# S32K324_M7 register map
Vendor: NXP Semiconductors; File version: 1.1
CPU: CM7 r0p1, little endian, MPU, FPU, VTOR, 4 interrupt priority bits
Registers are 32-bit, read-write, reset 0x0 unless marked. A register's access mark holds for its fields unless they carry their own. Offsets are from the block's base; [hi:lo] are bit positions; {n}, {i} and the like mark numbered series; 'fields as' and 'values as' point back to an identical list.

## EMAC (part 2 of 3)
Base 0x40480000
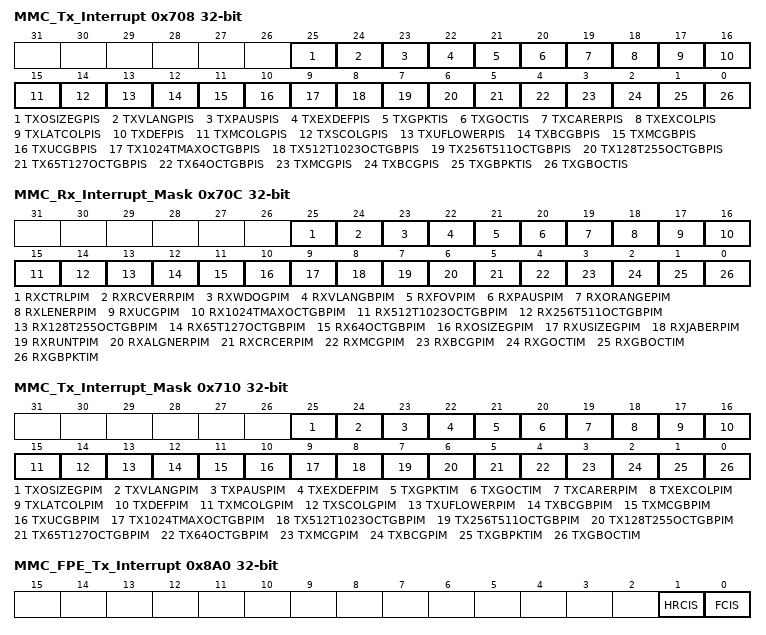
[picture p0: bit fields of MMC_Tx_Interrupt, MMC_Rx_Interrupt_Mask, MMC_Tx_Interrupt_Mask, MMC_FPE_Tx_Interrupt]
0x708 MMC_Tx_Interrupt ro — MMC Transmit Interrupt
  [all] fields
    0=INACTIVE (Not detected); 1=ACTIVE (Detected)
  [25] TXOSIZEGPIS — MMC Transmit Oversize Good Packet Counter Interrupt Status
  [24] TXVLANGPIS — MMC Transmit VLAN Good Packet Counter Interrupt Status
  [23] TXPAUSPIS — MMC Transmit Pause Packet Counter Interrupt Status
  [22] TXEXDEFPIS — MMC Transmit Excessive Deferral Packet Counter Interrupt Status
  [21] TXGPKTIS — MMC Transmit Good Packet Counter Interrupt Status
  [20] TXGOCTIS — MMC Transmit Good Octet Counter Interrupt Status
  [19] TXCARERPIS — MMC Transmit Carrier Error Packet Counter Interrupt Status
  [18] TXEXCOLPIS — MMC Transmit Excessive Collision Packet Counter Interrupt Status
  [17] TXLATCOLPIS — MMC Transmit Late Collision Packet Counter Interrupt Status
  [16] TXDEFPIS — MMC Transmit Deferred Packet Counter Interrupt Status
  [15] TXMCOLGPIS — MMC Transmit Multiple Collision Good Packet Counter Interrupt Status
  [14] TXSCOLGPIS — MMC Transmit Single Collision Good Packet Counter Interrupt Status
  [13] TXUFLOWERPIS — MMC Transmit Underflow Error Packet Counter Interrupt Status
  [12] TXBCGBPIS — MMC Transmit Broadcast Good Bad Packet Counter Interrupt Status
  [11] TXMCGBPIS — MMC Transmit Multicast Good Bad Packet Counter Interrupt Status
  [10] TXUCGBPIS — MMC Transmit Unicast Good Bad Packet Counter Interrupt Status
  [9] TX1024TMAXOCTGBPIS — MMC Transmit 1024 To Maximum Octet Good Bad Packet Counter Interrupt Status
  [8] TX512T1023OCTGBPIS — MMC Transmit 512 To 1023 Octet Good Bad Packet Counter Interrupt Status
  [7] TX256T511OCTGBPIS — MMC Transmit 256 To 511 Octet Good Bad Packet Counter Interrupt Status
  [6] TX128T255OCTGBPIS — MMC Transmit 128 To 255 Octet Good Bad Packet Counter Interrupt Status
  [5] TX65T127OCTGBPIS — MMC Transmit 65 To 127 Octet Good Bad Packet Counter Interrupt Status
  [4] TX64OCTGBPIS — MMC Transmit 64-Octet Good Bad Packet Counter Interrupt Status
  [3] TXMCGPIS — MMC Transmit Multicast Good Packet Counter Interrupt Status
  [2] TXBCGPIS — MMC Transmit Broadcast Good Packet Counter Interrupt Status
  [1] TXGBPKTIS — MMC Transmit Good Bad Packet Counter Interrupt Status
  [0] TXGBOCTIS — MMC Transmit Good Bad Octet Counter Interrupt Status
0x70C MMC_Rx_Interrupt_Mask — MMC Receive Interrupt Mask
  [all] fields
    0=DISABLE (Disabled); 1=ENABLE (Enabled)
  [25] RXCTRLPIM — MMC Receive Control Packet Counter Interrupt Mask
  [24] RXRCVERRPIM — MMC Receive Error Packet Counter Interrupt Mask
  [23] RXWDOGPIM — MMC Receive Watchdog Error Packet Counter Interrupt Mask
  [22] RXVLANGBPIM — MMC Receive VLAN Good Bad Packet Counter Interrupt Mask
  [21] RXFOVPIM — MMC Receive FIFO Overflow Packet Counter Interrupt Mask
  [20] RXPAUSPIM — MMC Receive Pause Packet Counter Interrupt Mask
  [19] RXORANGEPIM — MMC Receive Out-Of-Range Error Packet Counter Interrupt Mask
  [18] RXLENERPIM — MMC Receive Length Error Packet Counter Interrupt Mask
  [17] RXUCGPIM — MMC Receive Unicast Good Packet Counter Interrupt Mask
  [16] RX1024TMAXOCTGBPIM — MMC Receive 1024 To Maximum Octet Good Bad Packet Counter Interrupt Mask
  [15] RX512T1023OCTGBPIM — MMC Receive 512 To 1023 Octet Good Bad Packet Counter Interrupt Mask
  [14] RX256T511OCTGBPIM — MMC Receive 256 To 511 Octet Good Bad Packet Counter Interrupt Mask
  [13] RX128T255OCTGBPIM — MMC Receive 128 To 255 Octet Good Bad Packet Counter Interrupt Mask
  [12] RX65T127OCTGBPIM — MMC Receive 65 To 127 Octet Good Bad Packet Counter Interrupt Mask
  [11] RX64OCTGBPIM — MMC Receive 64-Octet Good Bad Packet Counter Interrupt Mask
  [10] RXOSIZEGPIM — MMC Receive Oversize Good Packet Counter Interrupt Mask
  [9] RXUSIZEGPIM — MMC Receive Undersize Good Packet Counter Interrupt Mask
  [8] RXJABERPIM — MMC Receive Jabber Error Packet Counter Interrupt Mask
  [7] RXRUNTPIM — MMC Receive Runt Packet Counter Interrupt Mask
  [6] RXALGNERPIM — MMC Receive Alignment Error Packet Counter Interrupt Mask
  [5] RXCRCERPIM — MMC Receive CRC Error Packet Counter Interrupt Mask
  [4] RXMCGPIM — MMC Receive Multicast Good Packet Counter Interrupt Mask
  [3] RXBCGPIM — MMC Receive Broadcast Good Packet Counter Interrupt Mask
  [2] RXGOCTIM — MMC Receive Good Octet Counter Interrupt Mask
  [1] RXGBOCTIM — MMC Receive Good Bad Octet Counter Interrupt Mask
  [0] RXGBPKTIM — MMC Receive Good Bad Packet Counter Interrupt Mask
0x710 MMC_Tx_Interrupt_Mask — MMC Transmit Interrupt Mask
  [all] fields
    0=DISABLE (Disabled); 1=ENABLE (Enabled)
  [25] TXOSIZEGPIM — MMC Transmit Oversize Good Packet Counter Interrupt Mask
  [24] TXVLANGPIM — MMC Transmit VLAN Good Packet Counter Interrupt Mask
  [23] TXPAUSPIM — MMC Transmit Pause Packet Counter Interrupt Mask
  [22] TXEXDEFPIM — MMC Transmit Excessive Deferral Packet Counter Interrupt Mask
  [21] TXGPKTIM — MMC Transmit Good Packet Counter Interrupt Mask
  [20] TXGOCTIM — MMC Transmit Good Octet Counter Interrupt Mask
  [19] TXCARERPIM — MMC Transmit Carrier Error Packet Counter Interrupt Mask
  [18] TXEXCOLPIM — MMC Transmit Excessive Collision Packet Counter Interrupt Mask
  [17] TXLATCOLPIM — MMC Transmit Late Collision Packet Counter Interrupt Mask
  [16] TXDEFPIM — MMC Transmit Deferred Packet Counter Interrupt Mask
  [15] TXMCOLGPIM — MMC Transmit Multiple Collision Good Packet Counter Interrupt Mask
  [14] TXSCOLGPIM — MMC Transmit Single Collision Good Packet Counter Interrupt Mask
  [13] TXUFLOWERPIM — MMC Transmit Underflow Error Packet Counter Interrupt Mask
  [12] TXBCGBPIM — MMC Transmit Broadcast Good Bad Packet Counter Interrupt Mask
  [11] TXMCGBPIM — MMC Transmit Multicast Good Bad Packet Counter Interrupt Mask
  [10] TXUCGBPIM — MMC Transmit Unicast Good Bad Packet Counter Interrupt Mask
  [9] TX1024TMAXOCTGBPIM — MMC Transmit 1024 To Maximum Octet Good Bad Packet Counter Interrupt Mask
  [8] TX512T1023OCTGBPIM — MMC Transmit 512 To 1023 Octet Good Bad Packet Counter Interrupt Mask
  [7] TX256T511OCTGBPIM — MMC Transmit 256 To 511 Octet Good Bad Packet Counter Interrupt Mask
  [6] TX128T255OCTGBPIM — MMC Transmit 128 To 255 Octet Good Bad Packet Counter Interrupt Mask
  [5] TX65T127OCTGBPIM — MMC Transmit 65 To 127 Octet Good Bad Packet Counter Interrupt Mask
  [4] TX64OCTGBPIM — MMC Transmit 64-Octet Good Bad Packet Counter Interrupt Mask
  [3] TXMCGPIM — MMC Transmit Multicast Good Packet Counter Interrupt Mask
  [2] TXBCGPIM — MMC Transmit Broadcast Good Packet Counter Interrupt Mask
  [1] TXGBPKTIM — MMC Transmit Good Bad Packet Counter Interrupt Mask
  [0] TXGBOCTIM — MMC Transmit Good Bad Octet Counter Interrupt Mask
0x714 Tx_Octet_Count_Good_Bad ro — Transmit Octet Count Good Bad
  [31:0] TXOCTGB
0x718 Tx_Packet_Count_Good_Bad ro — Transmit Packet Count Good Bad
  [31:0] TXPKTGB
0x71C Tx_Broadcast_Packets_Good ro — Transmit Broadcast Packets Good
  [31:0] TXBCASTG
0x720 Tx_Multicast_Packets_Good ro — Transmit Multicast Packets Good
  [31:0] TXMCASTG
0x724 Tx_64Octets_Packets_Good_Bad ro — Transmit 64-Octet Packets Good Bad
  [31:0] TX64OCTGB
0x728 Tx_65To127Octets_Packets_Good_Bad ro — Transmit 65 To 127 Octet Packets Good Bad
  [31:0] TX65_127OCTGB
0x72C Tx_128To255Octets_Packets_Good_Bad ro — Transmit 128 To 255 Octet Packets Good Bad
  [31:0] TX128_255OCTGB
0x730 Tx_256To511Octets_Packets_Good_Bad ro — Transmit 256 To 511 Octet Packets Good Bad
  [31:0] TX256_511OCTGB
0x734 Tx_512To1023Octets_Packets_Good_Bad ro — Transmit 512 To 1023 Octet Packets Good Bad
  [31:0] TX512_1023OCTGB
0x738 Tx_1024ToMaxOctets_Packets_Good_Bad ro — Transmit 1024 To Max Octet Packets Good Bad
  [31:0] TX1024_MAXOCTGB
0x73C Tx_Unicast_Packets_Good_Bad ro — Transmit Unicast Packets Good Bad
  [31:0] TXUCASTGB
0x740 Tx_Multicast_Packets_Good_Bad ro — Transmit Multicast Packets Good Bad
  [31:0] TXMCASTGB
0x744 Tx_Broadcast_Packets_Good_Bad ro — Transmit Broadcast Packets Good Bad
  [31:0] TXBCASTGB
0x748 Tx_Underflow_Error_Packets ro — Transmit Underflow Error Packets
  [31:0] TXUNDRFLW
0x74C Tx_Single_Collision_Good_Packets ro — Transmit Single Collision Good Packets
  [31:0] TXSNGLCOLG
0x750 Tx_Multiple_Collision_Good_Packets ro — Transmit Multiple Collision Good Packets
  [31:0] TXMULTCOLG
0x754 Tx_Deferred_Packets ro — Transmit Deferred Packets
  [31:0] TXDEFRD
0x758 Tx_Late_Collision_Packets ro — Transmit Late Collision Packets
  [31:0] TXLATECOL
0x75C Tx_Excessive_Collision_Packets ro — Transmit Excessive Collision Packets
  [31:0] TXEXSCOL
0x760 Tx_Carrier_Error_Packets ro — Transmit Carrier Error Packets
  [31:0] TXCARR
0x764 Tx_Octet_Count_Good ro — Transmit Octet Count Good
  [31:0] TXOCTG
0x768 Tx_Packet_Count_Good ro — Transmit Packet Count Good
  [31:0] TXPKTG
0x76C Tx_Excessive_Deferral_Error ro — Transmit Excessive Deferral Error
  [31:0] TXEXSDEF
0x770 Tx_Pause_Packets ro — Transmit Pause Packets
  [31:0] TXPAUSE
0x774 Tx_VLAN_Packets_Good ro — Transmit VLAN Packets Good
  [31:0] TXVLANG
0x778 Tx_OSize_Packets_Good ro — Transmit O Size Packets Good
  [31:0] TXOSIZG
0x780 Rx_Packets_Count_Good_Bad ro — Receive Packets Count Good Bad
  [31:0] RXPKTGB
0x784 Rx_Octet_Count_Good_Bad ro — Receive Octet Count Good Bad
  [31:0] RXOCTGB
0x788 Rx_Octet_Count_Good ro — Receive Octet Count Good
  [31:0] RXOCTG
0x78C Rx_Broadcast_Packets_Good ro — Receive Broadcast Packets Good
  [31:0] RXBCASTG
0x790 Rx_Multicast_Packets_Good ro — Receive Multicast Packets Good
  [31:0] RXMCASTG
0x794 Rx_CRC_Error_Packets ro — Receive CRC Error Packets
  [31:0] RXCRCERR
0x798 Rx_Alignment_Error_Packets ro — Receive Alignment Error Packets
  [31:0] RXALGNERR
0x79C Rx_Runt_Error_Packets ro — Receive Runt Error Packets
  [31:0] RXRUNTERR
0x7A0 Rx_Jabber_Error_Packets ro — Receive Jabber Error Packets
  [31:0] RXJABERR
0x7A4 Rx_Undersize_Packets_Good ro — Receive Undersize Packets Good
  [31:0] RXUNDERSZG
0x7A8 Rx_Oversize_Packets_Good ro — Receive Oversize Packets Good
  [31:0] RXOVERSZG
0x7AC Rx_64Octets_Packets_Good_Bad ro — Receive 64 Octets Packets Good Bad
  [31:0] RX64OCTGB
0x7B0 Rx_65To127Octets_Packets_Good_Bad ro — Receive 65-127 Octets Packets Good Bad
  [31:0] RX65_127OCTGB
0x7B4 Rx_128To255Octets_Packets_Good_Bad ro — Receive 128-255 Octets Packets Good Bad
  [31:0] RX128_255OCTGB
0x7B8 Rx_256To511Octets_Packets_Good_Bad ro — Receive 256-511 Octets Packets Good Bad
  [31:0] RX256_511OCTGB
0x7BC Rx_512To1023Octets_Packets_Good_Bad ro — Receive 512-1023 Octets Packets Good Bad
  [31:0] RX512_1023OCTGB
0x7C0 Rx_1024ToMaxOctets_Packets_Good_Bad ro — Receive 1024 To Max Octets Good Bad
  [31:0] RX1024_MAXOCTGB — Receive 1024-Max Octets Good Bad
0x7C4 Rx_Unicast_Packets_Good ro — Receive Unicast Packets Good
  [31:0] RXUCASTG
0x7C8 Rx_Length_Error_Packets ro — Receive Length Error Packets
  [31:0] RXLENERR
0x7CC Rx_Out_Of_Range_Type_Packets ro — Receive Out of Range Type Packet
  [31:0] RXOUTOFRNG
0x7D0 Rx_Pause_Packets ro — Receive Pause Packets
  [31:0] RXPAUSEPKT
0x7D4 Rx_FIFO_Overflow_Packets ro — Receive FIFO Overflow Packets
  [31:0] RXFIFOOVFL
0x7D8 Rx_VLAN_Packets_Good_Bad ro — Receive VLAN Packets Good Bad
  [31:0] RXVLANPKTGB
0x7DC Rx_Watchdog_Error_Packets ro — Receive Watchdog Error Packets
  [31:0] RXWDGERR
0x7E0 Rx_Receive_Error_Packets ro — Receive Receive Error Packets
  [31:0] RXRCVERR
0x7E4 Rx_Control_Packets_Good ro — Receive Control Packets Good
  [31:0] RXCTRLG
0x8A0 MMC_FPE_Tx_Interrupt ro — MMC Transmit FPE Fragment Counter Interrupt Status
  [1] HRCIS — MMC Transmit Hold Request Counter Interrupt Status
    0=INACTIVE (Not detected); 1=ACTIVE (Detected)
  [0] FCIS — MMC Transmit FPE Fragment Counter Interrupt Status
    0=INACTIVE (Not detected); 1=ACTIVE (Detected)
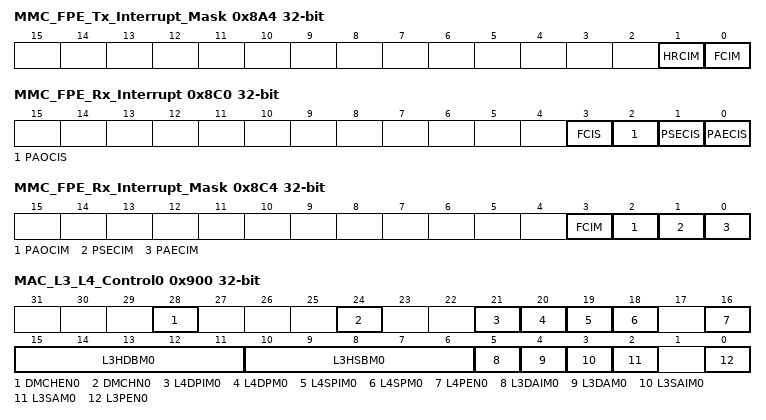
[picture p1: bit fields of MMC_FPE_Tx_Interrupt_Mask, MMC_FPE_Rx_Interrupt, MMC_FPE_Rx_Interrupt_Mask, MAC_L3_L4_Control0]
0x8A4 MMC_FPE_Tx_Interrupt_Mask — MMC FPE Transmit Interrupt Mask
  [1] HRCIM — MMC Transmit Hold Request Counter Interrupt Mask
    0=DISABLE (Disabled); 1=ENABLE (Enabled)
  [0] FCIM — MMC Transmit Fragment Counter Interrupt Mask
    0=DISABLE (Disabled); 1=ENABLE (Enabled)
0x8A8 MMC_Tx_FPE_Fragment_Cntr ro — Transmit FPE Fragment Counter
  [31:0] TXFFC
0x8AC MMC_Tx_Hold_Req_Cntr ro — Transmit Hold Request Counter
  [31:0] TXHRC
0x8C0 MMC_FPE_Rx_Interrupt ro — MMC Receive Packet Assembly Error Counter Interrupt Status
  [all] fields
    0=INACTIVE (Not detected); 1=ACTIVE (Detected)
  [3] FCIS — MMC Receive FPE Fragment Counter Interrupt Status
  [2] PAOCIS — MMC Receive Packet Assembly OK Counter Interrupt Status
  [1] PSECIS — MMC Receive, Transmit, Packet SMD Error Counter Interrupt Status
  [0] PAECIS — MMC Receive, transmit, Packet Assembly Error Counter Interrupt Status
0x8C4 MMC_FPE_Rx_Interrupt_Mask — MMC FPE Receive Interrupt Mask
  [all] fields
    0=DISABLE (Disabled); 1=ENABLE (Enabled)
  [3] FCIM — MMC Receive FPE Fragment Counter Interrupt Mask
  [2] PAOCIM — MMC Receive Packet Assembly OK Counter Interrupt Mask
  [1] PSECIM — MMC Receive Packet SMD Error Counter Interrupt Mask
  [0] PAECIM — MMC receive Packet Assembly Error Counter Interrupt Mask
0x8C8 MMC_Rx_Packet_Assembly_Err_Cntr ro — MMC Receive Packet Assembly Error Counter
  [31:0] PAEC — Packet Assembly Error Counter
0x8CC MMC_Rx_Packet_SMD_Err_Cntr ro — MMC Receive Packet SMD Error Counter
  [31:0] PSEC — Packet SMD Error Counter
0x8D0 MMC_Rx_Packet_Assembly_OK_Cntr ro — MMC Receive Packet Assembly OK Counter
  [31:0] PAOC — Packet Assembly OK Counter
0x8D4 MMC_Rx_FPE_Fragment_Cntr ro — MMC Receive FPE Fragment Counter
  [31:0] FFC — FPE Fragment Counter
0x900 MAC_L3_L4_Control0 — MAC Layer 3 Layer 4 Control 0
  [28] DMCHEN0 — DMA Channel Select Enable
    0=DISABLE (Disabled); 1=ENABLE (Enabled)
  [24] DMCHN0 — DMA Channel Number
  [21] L4DPIM0 — Layer 4 Destination Port Inverse Match Enable
    0=DISABLE (Disabled); 1=ENABLE (Enabled)
  [20] L4DPM0 — Layer 4 Destination Port Match Enable
    0=DISABLE (Disabled); 1=ENABLE (Enabled)
  [19] L4SPIM0 — Layer 4 Source Port Inverse Match Enable
    0=DISABLE (Disabled); 1=ENABLE (Enabled)
  [18] L4SPM0 — Layer 4 Source Port Match Enable
    0=DISABLE (Disabled); 1=ENABLE (Enabled)
  [16] L4PEN0 — Layer 4 Protocol Enable
    0=DISABLE (Disabled); 1=ENABLE (Enabled)
  [15:11] L3HDBM0 — Layer 3 IP DA Higher Bits Match
  [10:6] L3HSBM0 — Layer 3 IP SA Higher Bits Match
  [5] L3DAIM0 — Layer 3 IP DA Inverse Match Enable
    0=DISABLE (Disabled); 1=ENABLE (Enabled)
  [4] L3DAM0 — Layer 3 IP DA Match Enable
    0=DISABLE (Disabled); 1=ENABLE (Enabled)
  [3] L3SAIM0 — Layer 3 IP SA Inverse Match Enable
    0=DISABLE (Disabled); 1=ENABLE (Enabled)
  [2] L3SAM0 — Layer 3 IP SA Match Enable
    0=DISABLE (Disabled); 1=ENABLE (Enabled)
  [0] L3PEN0 — Layer 3 Protocol Enable
    0=DISABLE (Disabled); 1=ENABLE (Enabled)
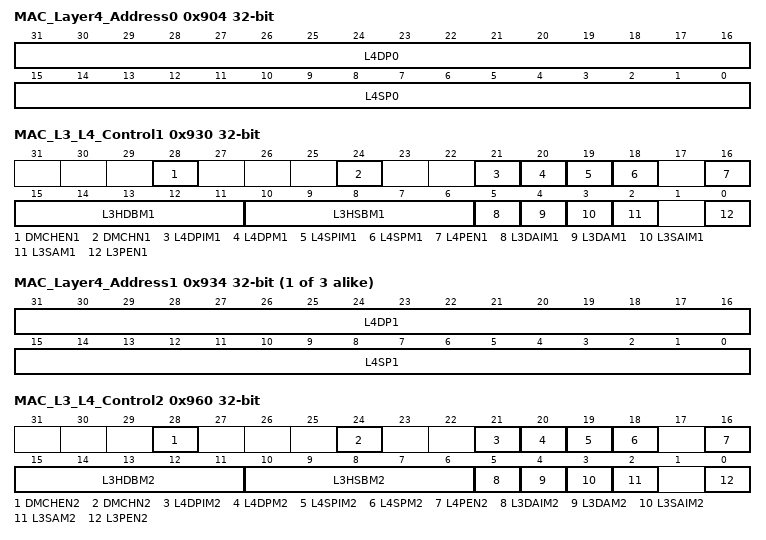
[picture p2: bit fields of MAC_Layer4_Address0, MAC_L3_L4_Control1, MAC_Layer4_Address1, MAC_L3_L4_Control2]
0x904 MAC_Layer4_Address0
  [31:16] L4DP0 — Layer 4 Destination Port Number
  [15:0] L4SP0 — Layer 4 Source Port Number
{0x910+4i} MAC_Layer3_Addr{i}_Reg0 (i=0..3) — MAC Layer 3 Address {i} Reg 0
  [31:0] L3A{10i:02} — Layer 3 Address {i}
0x930 MAC_L3_L4_Control1
  [28] DMCHEN1 — DMA Channel Select Enable 1
    0=DISABLE (Disabled); 1=ENABLE (Enabled)
  [24] DMCHN1 — DMA Channel Number 1
  [21] L4DPIM1 — Layer 4 Destination Port Inverse Match Enable 1
    0=DISABLE (Disabled); 1=ENABLE (Enabled)
  [20] L4DPM1 — Layer 4 Destination Port Match Enable 1
    0=DISABLE (Disabled); 1=ENABLE (Enabled)
  [19] L4SPIM1 — Layer 4 Source Port Inverse Match Enable 1
    0=DISABLE (Disabled); 1=ENABLE (Enabled)
  [18] L4SPM1 — Layer 4 Source Port Match Enable 1
    0=DISABLE (Disabled); 1=ENABLE (Enabled)
  [16] L4PEN1 — Layer 4 Protocol Enable 1
    0=DISABLE (Disabled); 1=ENABLE (Enabled)
  [15:11] L3HDBM1 — Layer 3 IP DA Higher Bits Match 1
  [10:6] L3HSBM1 — Layer 3 IP SA Higher Bits Match 1
  [5] L3DAIM1 — Layer 3 IP DA Inverse Match Enable 1
    0=DISABLE (Disabled); 1=ENABLE (Enabled)
  [4] L3DAM1 — Layer 3 IP DA Match Enable 1
    0=DISABLE (Disabled); 1=ENABLE (Enabled)
  [3] L3SAIM1 — Layer 3 IP SA Inverse Match Enable 1
    0=DISABLE (Disabled); 1=ENABLE (Enabled)
  [2] L3SAM1 — Layer 3 IP SA Match Enable 1
    0=DISABLE (Disabled); 1=ENABLE (Enabled)
  [0] L3PEN1 — Layer 3 Protocol Enable 1
    0=DISABLE (Disabled); 1=ENABLE (Enabled)
{0x904+0x30*i} MAC_Layer4_Address{i} (i=1..3)
  [31:16] L4DP{i} — Layer 4 Destination Port Number {i}
  [15:0] L4SP{i} — Layer 4 Source Port Number {i}
{0x940+4i} MAC_Layer3_Addr{i}_Reg1 (i=0..3) — MAC Layer 3 Address {i} Reg 1
  [31:0] L3A{10i+1:02} — Layer 3 Address {i}
0x960 MAC_L3_L4_Control2
  [28] DMCHEN2 — DMA Channel Select Enable 2
    0=DISABLE (Disabled); 1=ENABLE (Enabled)
  [24] DMCHN2 — DMA Channel Number 2
  [21] L4DPIM2 — Layer 4 Destination Port Inverse Match Enable 2
    0=DISABLE (Disabled); 1=ENABLE (Enabled)
  [20] L4DPM2 — Layer 4 Destination Port Match Enable 2
    0=DISABLE (Disabled); 1=ENABLE (Enabled)
  [19] L4SPIM2 — Layer 4 Source Port Inverse Match Enable 2
    0=DISABLE (Disabled); 1=ENABLE (Enabled)
  [18] L4SPM2 — Layer 4 Source Port Match Enable 2
    0=DISABLE (Disabled); 1=ENABLE (Enabled)
  [16] L4PEN2 — Layer 4 Protocol Enable 2
    0=DISABLE (Disabled); 1=ENABLE (Enabled)
  [15:11] L3HDBM2 — Layer 3 IP DA Higher Bits Match 2
  [10:6] L3HSBM2 — Layer 3 IP SA Higher Bits Match 2
  [5] L3DAIM2 — Layer 3 IP DA Inverse Match Enable 2
    0=DISABLE (Disabled); 1=ENABLE (Enabled)
  [4] L3DAM2 — Layer 3 IP DA Match Enable 2
    0=DISABLE (Disabled); 1=ENABLE (Enabled)
  [3] L3SAIM2 — Layer 3 IP SA Inverse Match Enable 2
    0=DISABLE (Disabled); 1=ENABLE (Enabled)
  [2] L3SAM2 — Layer 3 IP SA Match Enable 2
    0=DISABLE (Disabled); 1=ENABLE (Enabled)
  [0] L3PEN2 — Layer 3 Protocol Enable 2
    0=DISABLE (Disabled); 1=ENABLE (Enabled)
{0x970+4i} MAC_Layer3_Addr{i}_Reg2 (i=0..3) — MAC Layer 3 Address {i} Reg 2
  [31:0] L3A{10i+2:02} — Layer 3 Address {i}
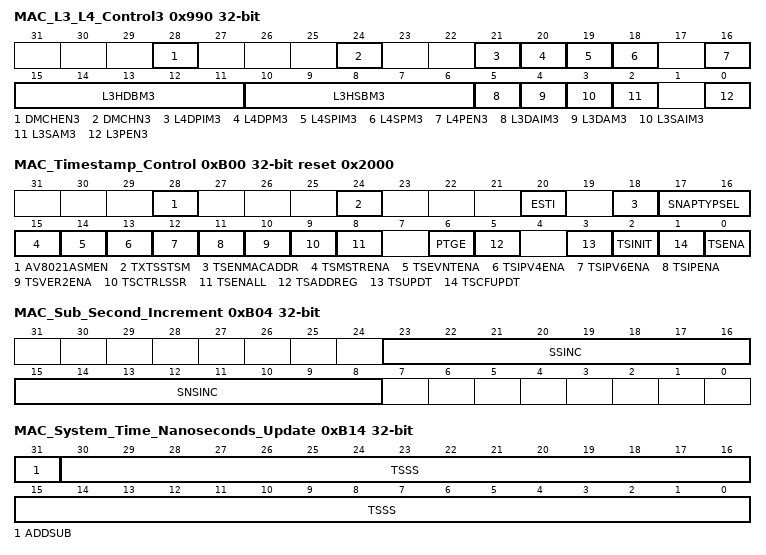
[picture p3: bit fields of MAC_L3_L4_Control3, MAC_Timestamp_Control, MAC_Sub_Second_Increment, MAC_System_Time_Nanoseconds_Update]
0x990 MAC_L3_L4_Control3
  [28] DMCHEN3 — DMA Channel Select Enable 3
    0=DISABLE (Disabled); 1=ENABLE (Enabled)
  [24] DMCHN3 — DMA Channel Number 2
  [21] L4DPIM3 — Layer 4 Destination Port Inverse Match Enable 3
    0=DISABLE (Disabled); 1=ENABLE (Enabled)
  [20] L4DPM3 — Layer 4 Destination Port Match Enable 3
    0=DISABLE (Disabled); 1=ENABLE (Enabled)
  [19] L4SPIM3 — Layer 4 Source Port Inverse Match Enable 3
    0=DISABLE (Disabled); 1=ENABLE (Enabled)
  [18] L4SPM3 — Layer 4 Source Port Match Enable 3
    0=DISABLE (Disabled); 1=ENABLE (Enabled)
  [16] L4PEN3 — Layer 4 Protocol Enable 3
    0=DISABLE (Disabled); 1=ENABLE (Enabled)
  [15:11] L3HDBM3 — Layer 3 IP DA Higher Bits Match 3
  [10:6] L3HSBM3 — Layer 3 IP SA Higher Bits Match 3
  [5] L3DAIM3 — Layer 3 IP DA Inverse Match Enable 3
    0=DISABLE (Disabled); 1=ENABLE (Enabled)
  [4] L3DAM3 — Layer 3 IP DA Match Enable 3
    0=DISABLE (Disabled); 1=ENABLE (Enabled)
  [3] L3SAIM3 — Layer 3 IP SA Inverse Match Enable 3
    0=DISABLE (Disabled); 1=ENABLE (Enabled)
  [2] L3SAM3 — Layer 3 IP SA Match Enable 3
    0=DISABLE (Disabled); 1=ENABLE (Enabled)
  [0] L3PEN3 — Layer 3 Protocol Enable 3
    0=DISABLE (Disabled); 1=ENABLE (Enabled)
{0x9A0+4i} MAC_Layer3_Addr{i}_Reg3 (i=0..3) — MAC Layer 3 Address {i} Reg 3
  [31:0] L3A{10i+3:02} — Layer 3 Address {i}
0xB00 MAC_Timestamp_Control reset 0x2000
  [28] AV8021ASMEN — AV 802.1AS Mode Enable
    0=DISABLE (Disabled); 1=ENABLE (Enabled)
  [24] TXTSSTSM — Transmit Timestamp Status Mode
    0=DISABLE (Disabled); 1=ENABLE (Enabled)
  [20] ESTI — External System Time Input
    0=DISABLE (Disabled); 1=ENABLE (Enabled)
  [18] TSENMACADDR — Enable MAC Address For PTP Packet Filtering
    0=DISABLE (Disabled); 1=ENABLE (Enabled)
  [17:16] SNAPTYPSEL — Select PTP Packets For Taking Snapshots
  [15] TSMSTRENA — Enable Snapshot For Messages Relevant To Master
    0=DISABLE (Disabled); 1=ENABLE (Enabled)
  [14] TSEVNTENA — Enable Timestamp Snapshot For Event Messages
    0=DISABLE (Disabled); 1=ENABLE (Enabled)
  [13] TSIPV4ENA — Enable Processing Of PTP Packets Sent Over IPv4-UDP
    0=DISABLE (Disabled); 1=ENABLE (Enabled)
  [12] TSIPV6ENA — Enable Processing Of PTP Packets Sent Over IPv6-UDP
    0=DISABLE (Disabled); 1=ENABLE (Enabled)
  [11] TSIPENA — Enable Processing Of PTP Over Ethernet Packets
    0=DISABLE (Disabled); 1=ENABLE (Enabled)
  [10] TSVER2ENA — Enable PTP Packet Processing For Version 2 Format
    0=DISABLE (Disabled); 1=ENABLE (Enabled)
  [9] TSCTRLSSR — Timestamp Digital Or Binary Rollover Control
    0=DISABLE (Disabled); 1=ENABLE (Enabled)
  [8] TSENALL — Enable Timestamp For All Packets
    0=DISABLE (Disabled); 1=ENABLE (Enabled)
  [6] PTGE — Presentation Time Generation Enable
    0=DISABLE (Disabled); 1=ENABLE (Enabled)
  [5] TSADDREG — Update Addend Register
    0=DISABLE (Not updated); 1=ENABLE (Updated)
  [3] TSUPDT — Update Timestamp
    0=DISABLE (Not updated); 1=ENABLE (Updated)
  [2] TSINIT — Initialize Timestamp
    0=DISABLE (Not initialized); 1=ENABLE (Initialized)
  [1] TSCFUPDT — Fine Or Coarse Timestamp Update
    0=COARSE (Coarse method); 1=FINE (Fine method)
  [0] TSENA — Timestamp Enable
    0=DISABLE (Disabled); 1=ENABLE (Enabled)
0xB04 MAC_Sub_Second_Increment
  [23:16] SSINC — Sub-Second Increment Value
  [15:8] SNSINC — Sub-Nanosecond Increment Value
0xB08 MAC_System_Time_Seconds ro — MAC System Time In Seconds
  [31:0] TSS — Timestamp Second
0xB0C MAC_System_Time_Nanoseconds ro — MAC System Time In Nanoseconds
  [30:0] TSSS — Timestamp Sub Seconds
0xB10 MAC_System_Time_Seconds_Update
  [31:0] TSS — Timestamp Seconds
0xB14 MAC_System_Time_Nanoseconds_Update
  [31] ADDSUB — Add Or Subtract Time
    0=ADD (Add time); 1=SUB (Subtract time)
  [30:0] TSSS — Timestamp Subseconds
0xB18 MAC_Timestamp_Addend
  [31:0] TSAR — Timestamp Addend Register
0xB1C MAC_System_Time_Higher_Word_Seconds — MAC System Time Higher Word In Seconds
  [15:0] TSHWR — Timestamp Higher Word Register
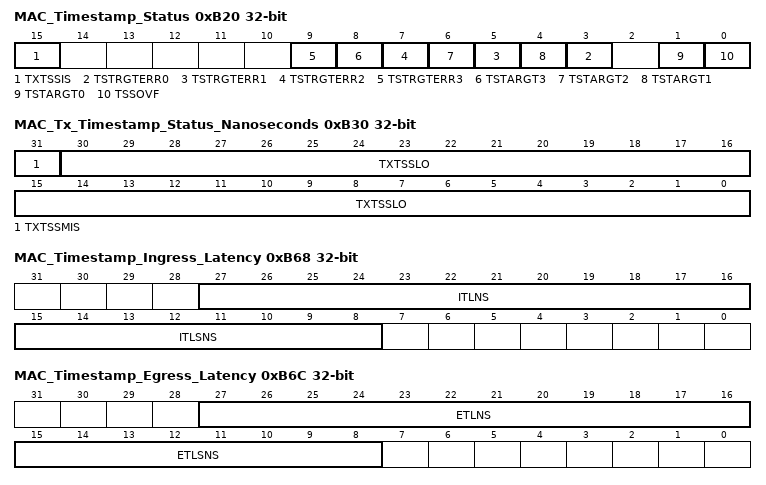
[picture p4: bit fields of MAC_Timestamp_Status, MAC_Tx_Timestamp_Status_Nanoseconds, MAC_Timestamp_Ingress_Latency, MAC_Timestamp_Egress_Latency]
0xB20 MAC_Timestamp_Status ro
  [all] fields
    0=INACTIVE (Not detected); 1=ACTIVE (Detected)
  [15] TXTSSIS — Transmit Timestamp Status Interrupt Status
  [2n+3] TSTRGTERR{n} (n=0..3) — Timestamp Target Time Error
  [8] TSTARGT3 — Timestamp Target Time Reached For Target Time PPS3
  [6] TSTARGT2 — Timestamp Target Time Reached For Target Time PPS2
  [4] TSTARGT1 — Timestamp Target Time Reached For Target Time PPS1
  [1] TSTARGT0 — Timestamp Target Time Reached
  [0] TSSOVF — Timestamp Seconds Overflow
0xB30 MAC_Tx_Timestamp_Status_Nanoseconds ro — MAC Transmit Timestamp Status In Nanoseconds
  [31] TXTSSMIS — Transmit Timestamp Status Missed
    0=INACTIVE (Not detected); 1=ACTIVE (Detected)
  [30:0] TXTSSLO — Transmit Timestamp Status Low
0xB34 MAC_Tx_Timestamp_Status_Seconds ro — MAC Transmit Timestamp Status In Seconds
  [31:0] TXTSSHI — Transmit Timestamp Status High
0xB50 MAC_Timestamp_Ingress_Asym_Corr — MAC Timestamp Ingress Asymmetry Correction
  [31:0] OSTIAC — One-Step Timestamp Ingress Asymmetry Correction
0xB54 MAC_Timestamp_Egress_Asym_Corr — MAC Timestamp Egress Asymmetry Correction
  [31:0] OSTEAC — One-Step Timestamp Egress Asymmetry Correction
0xB58 MAC_Timestamp_Ingress_Corr_Nanosecond — MAC Timestamp Ingress Correction In Nanoseconds
  [31:0] TSIC — Timestamp Ingress Correction
0xB5C MAC_Timestamp_Egress_Corr_Nanosecond — MAC Timestamp Egress Correction In Nanoseconds
  [31:0] TSEC — Timestamp Egress Correction
0xB60 MAC_Timestamp_Ingress_Corr_Subnanosec — MAC Timestamp Ingress Correction In Subnanoseconds
  [15:8] TSICSNS — Timestamp Ingress Correction In Sub-Nanoseconds
0xB64 MAC_Timestamp_Egress_Corr_Subnanosec — MAC Timestamp Engress Correction In Subnanoseconds
  [15:8] TSECSNS — Timestamp Egress Correction In Sub-Nanoseconds
0xB68 MAC_Timestamp_Ingress_Latency ro
  [27:16] ITLNS — Ingress Timestamp Latency In Sub-Nanoseconds
  [15:8] ITLSNS — Ingress Timestamp Latency In Nanoseconds
0xB6C MAC_Timestamp_Egress_Latency ro — MAC Timestamp Egress Latecy
  [27:16] ETLNS — Egress Timestamp Latency In Nanoseconds
  [15:8] ETLSNS — Egress Timestamp Latency In Sub-Nanoseconds
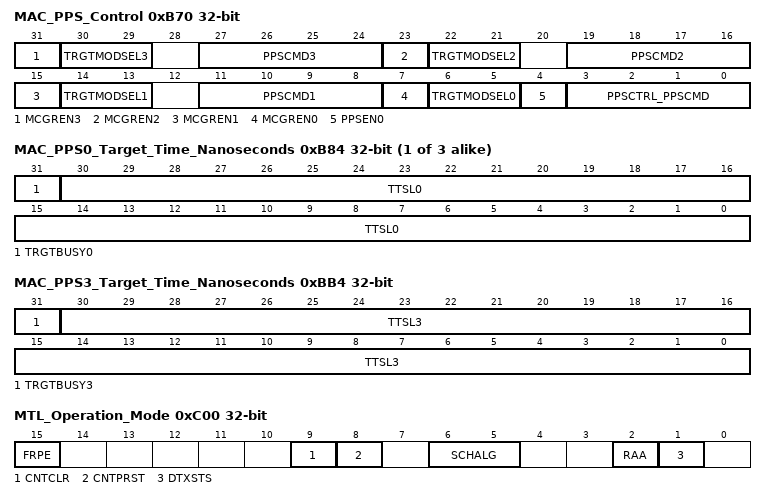
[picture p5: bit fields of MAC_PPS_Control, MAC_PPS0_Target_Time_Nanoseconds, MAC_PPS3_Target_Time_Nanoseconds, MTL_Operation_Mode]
0xB70 MAC_PPS_Control
  [31] MCGREN3 — MCGR Mode Enable For PPS3 Output
  [30:29] TRGTMODSEL3 — Target Time Register Mode For PPS3 Output
    0=ONLY_INT (Target Time registers are programmed only for generating the interrupt event. The flexible PPS function must not be enabled in this mode, otherwise spurious transitions may be observed on the corresponding ptp_pps_o output port.); 2=INT_ST (Target Time registers are programmed for generating the interrupt event and starting or stopping the PPS0 output signal generation.); 3=ONLY_ST (Target Time registers are programmed only for starting or stopping the PPS0 output signal generation. No interrupt is asserted.)
  [27:24] PPSCMD3 — Flexible PPS3 Output Control
  [23] MCGREN2 — MCGR Mode Enable For PPS2 Output
    0=DISABLE (Disabled); 1=ENABLE (Enabled)
  [22:21] TRGTMODSEL2 — Target Time Register Mode For PPS2 Output
    values as TRGTMODSEL3
  [19:16] PPSCMD2 — Flexible PPS2 Output Control
  [15] MCGREN1 — MCGR Mode Enable For PPS1 Output
    0=DISABLE (Disabled); 1=ENABLE (Enabled)
  [14:13] TRGTMODSEL1 — Target Time Register Mode For PPS1 Output
    0=ONLY_INT (Target Time registers are programmed only for generating the interrupt event. The flexible PPS function must not be 1 in this mode, otherwise spurious transitions may be observed on the corresponding ptp_pps_o output port.); 2=INT_ST (Target Time registers are programmed for generating the interrupt event and starting or stopping the PPS0 output signal generation.); 3=ONLY_ST (Target Time registers are programmed only for starting or stopping the PPS0 output signal generation. No interrupt is asserted.)
  [11:8] PPSCMD1 — Flexible PPS1 Output Control
  [7] MCGREN0 — MCGR Mode Enable For PPS0 Output
    0=PPS (PPS mode); 1=MCGR (MCGR mode)
  [6:5] TRGTMODSEL0 — Target Time Register Mode For PPS0 Output
    values as TRGTMODSEL1
  [4] PPSEN0 — Flexible PPS Output Mode Enable 0
    0=DISABLE (Disabled); 1=ENABLE (Enabled)
  [3:0] PPSCTRL_PPSCMD — PPS Output Frequency Control
0xB80 MAC_PPS0_Target_Time_Seconds — MAC PPS0 Target Time In Seconds
  [31:0] TSTRH0 — PPS Target Time In Seconds Register
{0xB84+0x10*i} MAC_PPS{i}_Target_Time_Nanoseconds (i=0..2) — MAC PPS{i} Target Time In Nanoseconds
  [31] TRGTBUSY{i} — PPS Target Time Busy Status {i}
    0=INACTIVE (Not detected); 1=ACTIVE (Detected)
  [30:0] TTSL{i} — Target Time Low For PPS{i}
{0xB88+0x10*i} MAC_PPS{i}_Interval (i=0..2)
  [31:0] PPSINT{i} — PPS Output Signal Interval {i}
{0xB8C+0x10*i} MAC_PPS{i}_Width (i=0..3)
  [31:0] PPSWIDTH{i} — PPS Output Signal Width {i}
0xB90 MAC_PPS1_Target_Time_Seconds — MAC PPS1 Target Time In Seconds
  [31:0] TSTRH1 — PPS Target Time In Seconds 1
0xBA0 MAC_PPS2_Target_Time_Seconds — MAC PPS2 Taget Time In Seconds
  [31:0] TSTRH2 — PPS Target Time In Seconds 2
0xBB0 MAC_PPS3_Target_Time_Seconds — MAC PPS3 Target Time In Seconds
  [31:0] TSTRH3 — PPS Target Time In Seconds 3
0xBB4 MAC_PPS3_Target_Time_Nanoseconds — MAC PPS3 Target Time In Nanoseconds
  [31] TRGTBUSY3 — PPS Target Time Register Busy 3
    0=INACTIVE (Not detected); 1=ACTIVE (Detected)
  [30:0] TTSL3 — Target Time Low For PPS3
0xBB8 MAC_PPS3_Interval
  [31:0] PPSINT3 — PPS Output Signal Interval
0xC00 MTL_Operation_Mode
  [15] FRPE — Flexible Receive Parser Enable
    0=DISABLE (Disabled); 1=ENABLE (Enabled)
  [9] CNTCLR — Counters Reset
    0=DISABLE (Not reset); 1=ENABLE (Reset)
  [8] CNTPRST — Counters Preset
    0=DISABLE (Disabled); 1=ENABLE (Enabled)
  [6:5] SCHALG — Transmit Scheduling Algorithm
    0=WRR (WRR algorithm); 1=WFQ (WFQ algorithm when DCB feature selected; otherwise, reserved); 2=DWRR (DWRR algorithm when DCB feature selected; otherwise, reserved); 3=SP (Strict priority algorithm)
  [2] RAA — Receive Arbitration Algorithm
    0=SP (Strict priority (SP)); 1=WSP (Weighted strict priority (WSP))
  [1] DTXSTS — Drop Transmit Status
    0=DISABLE (Disabled); 1=ENABLE (Enabled)
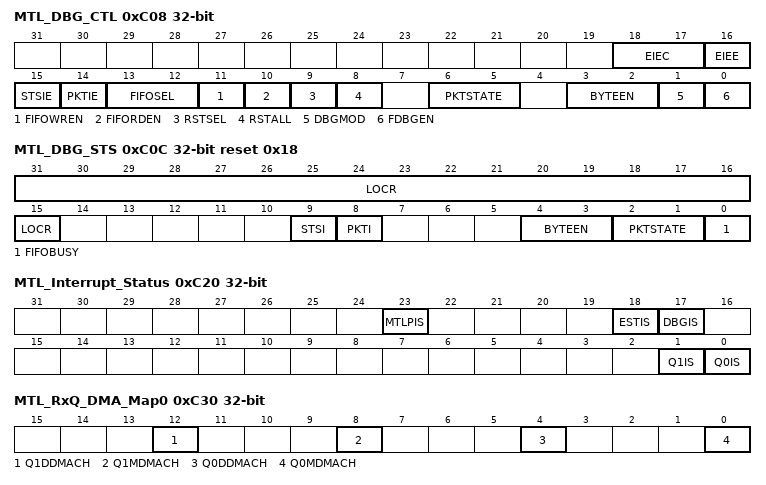
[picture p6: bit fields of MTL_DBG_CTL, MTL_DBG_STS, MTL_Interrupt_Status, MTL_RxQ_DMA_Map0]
0xC08 MTL_DBG_CTL — MTL Debug Control
  [18:17] EIEC — ECC Inject Error Control
    0=M_1BIT (1-bit error); 1=M_2BIT (2-bit errors); 2=M_3BIT (3-bit errors); 3=M_1BIT_ADDR (1-bit error in the address field)
  [16] EIEE — ECC Inject Error Enable
    0=DISABLE (Disabled); 1=ENABLE (Enabled)
  [15] STSIE — Transmit Status Available Interrupt Status Enable
    0=DISABLE (Disabled); 1=ENABLE (Enabled)
  [14] PKTIE — Receive Packet Available Interrupt Status Enable
    0=DISABLE (Disabled); 1=ENABLE (Enabled)
  [13:12] FIFOSEL — FIFO Selected for Access
    0=TXFIFO (Transmit FIFO); 1=TXSTSFIFO (Transmit status FIFO (only read access when SLVMOD is set)); 2=TSOFIFO (TSO FIFO (cannot be accessed when SLVMOD is set)); 3=RXFIFO (Receive FIFO)
  [11] FIFOWREN — FIFO Write Enable
    0=DISABLE (Disabled); 1=ENABLE (Enabled)
  [10] FIFORDEN — FIFO Read Enable
    0=DISABLE (Disabled); 1=ENABLE (Enabled)
  [9] RSTSEL — Reset Pointers Of Selected FIFO
    0=DISABLE (Disabled); 1=ENABLE (Enabled)
  [8] RSTALL — Reset All Pointers
    0=DISABLE (Disabled); 1=ENABLE (Enabled)
  [6:5] PKTSTATE — Encoded Packet State
    0=PKT_DATA (Packet data); 1=CW_NS (Control word/normal status); 2=SOP_LS (SOP data/last status); 3=EOP (EOP data/EOP)
  [3:2] BYTEEN — Byte Enables
    0=B0_VAL (Byte 0 valid); 1=B01_VAL (Byte 0 and byte 1 valid); 2=B012_VAL (Byte 0, byte 1, and byte 2 valid); 3=B0123_VAL (All four bytes valid)
  [1] DBGMOD — Debug Mode Access to FIFO
    0=DISABLE (Disabled); 1=ENABLE (Enabled)
  [0] FDBGEN — FIFO Debug Access Enable
    0=DISABLE (Disabled); 1=ENABLE (Enabled)
0xC0C MTL_DBG_STS reset 0x18 — MTL Debug Status
  [31:15] LOCR ro — Remaining Locations In FIFO
  [9] STSI — Transmit Status Available Interrupt Status
    0=INACTIVE (Not detected); 1=ACTIVE (Detected)
  [8] PKTI — Receive Packet Available Interrupt Status
    0=INACTIVE (Not detected); 1=ACTIVE (Detected)
  [4:3] BYTEEN ro — Byte Enables
    values as MTL_DBG_CTL.BYTEEN
  [2:1] PKTSTATE ro — Encoded Packet State
    values as MTL_DBG_CTL.PKTSTATE
  [0] FIFOBUSY ro
    0=INACTIVE (Not detected); 1=ACTIVE (Detected)
0xC10 MTL_FIFO_Debug_Data
  [31:0] FDBGDATA — FIFO Debug Data
0xC20 MTL_Interrupt_Status ro
  [all] fields
    0=INACTIVE (Not detected); 1=ACTIVE (Detected)
  [23] MTLPIS — MTL Receive Parser Interrupt Status
  [18] ESTIS — EST (TAS- 802.1Qbv) Interrupt Status
  [17] DBGIS — Debug Interrupt Status
  [1] Q1IS — Queue 1 Interrupt Status
  [0] Q0IS — Queue 0 Interrupt Status
0xC30 MTL_RxQ_DMA_Map0 — MTL Receive Queue DMA Map 0
  [12] Q1DDMACH — Queue 1 Enabled for DA-based DMA Channel Selection
    0=DISABLE (Disabled); 1=ENABLE (Enabled)
  [8] Q1MDMACH — Queue 1 Mapped to DMA Channel
  [4] Q0DDMACH — Queue 0 Enabled for DA-based DMA Channel Selection
    0=DISABLE; 1=ENABLE
  [0] Q0MDMACH — Queue 0 Mapped to DMA Channel
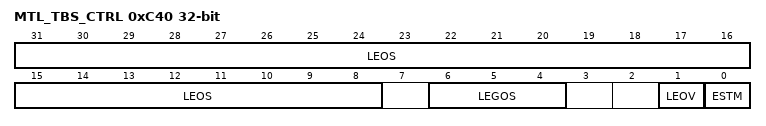
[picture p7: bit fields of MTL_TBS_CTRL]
0xC40 MTL_TBS_CTRL — MTL TBS Control
  [31:8] LEOS — Launch Expiry Offset
  [6:4] LEGOS — Launch Expiry GSN Offset
  [1] LEOV — Launch Expiry Offset Valid
    0=INVALID; 1=VALID
  [0] ESTM — EST offset Mode
    0=DISABLE (Disabled); 1=ENABLE (Enabled)
